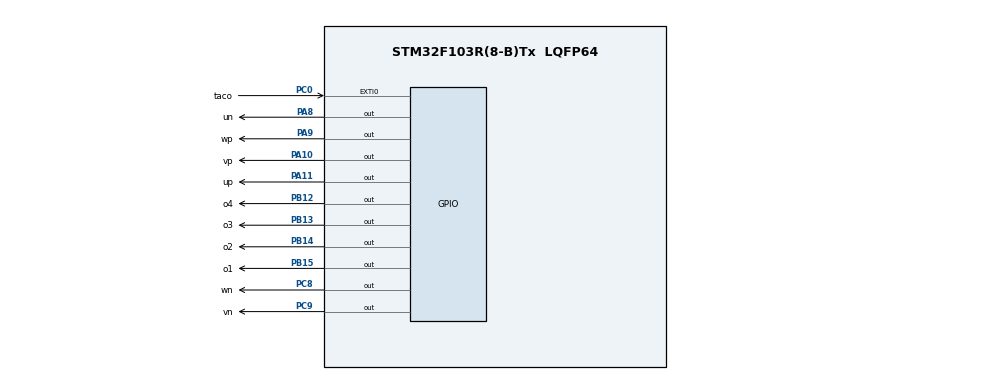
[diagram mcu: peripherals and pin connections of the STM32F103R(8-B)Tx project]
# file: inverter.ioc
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Mcu.Family=STM32F1
Mcu.Name=STM32F103R(8-B)Tx
Mcu.Package=LQFP64
NVIC.EXTI0_IRQn=true\:1\:0\:true\:false\:true\:true\:true
NVIC.PriorityGroup=NVIC_PRIORITYGROUP_4
NVIC.TIM1_UP_IRQn=true\:0\:0\:false\:false\:true\:true\:true
NVIC.TIM4_IRQn=true\:0\:0\:false\:false\:true\:false\:true
NVIC.TimeBase=TIM4_IRQn
NVIC.TimeBaseIP=TIM4
PA10.GPIO_Label=vp
PA10.GPIO_Speed=GPIO_SPEED_FREQ_HIGH
PA10.Signal=GPIO_Output
PA11.GPIO_Label=up
PA11.GPIO_Speed=GPIO_SPEED_FREQ_HIGH
PA11.Signal=GPIO_Output
PA13.Mode=Serial_Wire
PA13.Signal=SYS_JTMS-SWDIO
PA14.Mode=Serial_Wire
PA14.Signal=SYS_JTCK-SWCLK
PA8.GPIO_Label=un
PA8.GPIO_Speed=GPIO_SPEED_FREQ_HIGH
PA8.PinState=GPIO_PIN_RESET
PA8.Signal=GPIO_Output
PA9.GPIO_Label=wp
PA9.GPIO_Speed=GPIO_SPEED_FREQ_HIGH
PA9.Signal=GPIO_Output
PB12.GPIO_Label=o4
PB12.GPIO_Speed=GPIO_SPEED_FREQ_HIGH
PB12.Signal=GPIO_Output
PB13.GPIO_Label=o3
PB13.GPIO_Speed=GPIO_SPEED_FREQ_HIGH
PB13.Signal=GPIO_Output
PB14.GPIO_Label=o2
PB14.GPIO_Speed=GPIO_SPEED_FREQ_HIGH
PB14.Signal=GPIO_Output
PB15.GPIO_Label=o1
PB15.GPIO_Speed=GPIO_SPEED_FREQ_HIGH
PB15.Signal=GPIO_Output
PC0.GPIO_Label=taco
PC0.Signal=GPXTI0
PC8.GPIO_Label=wn
PC8.GPIO_Speed=GPIO_SPEED_FREQ_HIGH
PC8.Signal=GPIO_Output
PC9.GPIO_Label=vn
PC9.GPIO_Speed=GPIO_SPEED_FREQ_HIGH
PC9.Signal=GPIO_Output
PD0-OSC_IN.Mode=HSE-External-Oscillator
PD0-OSC_IN.Signal=RCC_OSC_IN
PD1-OSC_OUT.Mode=HSE-External-Oscillator
PD1-OSC_OUT.Signal=RCC_OSC_OUT
ProjectManager.HeapSize=0x200
ProjectManager.StackSize=0x400
ProjectManager.TargetToolchain=STM32CubeIDE
RCC.AHBFreq_Value=72000000
RCC.APB1CLKDivider=RCC_HCLK_DIV2
RCC.APB1Freq_Value=36000000
RCC.APB1TimFreq_Value=72000000
RCC.APB2Freq_Value=72000000
RCC.APB2TimFreq_Value=72000000
RCC.HCLKFreq_Value=72000000
RCC.PLLMUL=RCC_PLL_MUL9
RCC.PLLSourceVirtual=RCC_PLLSOURCE_HSE
RCC.SYSCLKFreq_VALUE=72000000
RCC.SYSCLKSource=RCC_SYSCLKSOURCE_PLLCLK
RCC.USBFreq_Value=72000000
TIM1.Period=0
TIM1.Prescaler=36
TIM1.RepetitionCounter=2
VP_SYS_VS_tim4.Mode=TIM4
VP_TIM1_VS_ClockSourceINT.Mode=Internal
board=custom

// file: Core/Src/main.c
/* USER CODE BEGIN Header */
/**
 ******************************************************************************
 * @file           : main.c
 * @brief          : Main program body
 ******************************************************************************
 * @attention
 *
 * <h2><center>&copy; Copyright (c) 2021 STMicroelectronics.
 * All rights reserved.</center></h2>
 *
 * This software component is licensed by ST under BSD 3-Clause license,
 * the "License"; You may not use this file except in compliance with the
 * License. You may obtain a copy of the License at:
 *                        opensource.org/licenses/BSD-3-Clause
 *
 ******************************************************************************
 */
/* USER CODE END Header */
#include "main.h"
#include "tim.h"
#include "gpio.h"

void SystemClock_Config(void);

int main(void)
{

	/* MCU Configuration--------------------------------------------------------*/

	/* Reset of all peripherals, Initializes the Flash interface and the Systick. */
	HAL_Init();

	/* Configure the system clock */
	SystemClock_Config();

	/* Initialize all configured peripherals */
	MX_GPIO_Init();
	MX_TIM1_Init();
	/* USER CODE BEGIN 2 */
	LL_TIM_EnableCounter(TIM1);
	LL_TIM_EnableIT_UPDATE(TIM1);
	/* USER CODE END 2 */

	/* Infinite loop */
	/* USER CODE BEGIN WHILE */

	//LL_GPIO_TogglePin(GPIOC, LL_GPIO_PIN_13);
	//LL_GPIO_SetOutputPin(o1_GPIO_Port, o1_Pin);
	//LL_GPIO_ResetOutputPin(o1_GPIO_Port, o1_Pin);
	while (1)
	{
		/* USER CODE END WHILE */

	}
}

void SystemClock_Config(void)
{
	LL_FLASH_SetLatency(LL_FLASH_LATENCY_2);
	while(LL_FLASH_GetLatency()!= LL_FLASH_LATENCY_2)
	{
	}
	LL_RCC_HSE_Enable();

	/* Wait till HSE is ready */
	while(LL_RCC_HSE_IsReady() != 1)
	{

	}
	LL_RCC_PLL_ConfigDomain_SYS(LL_RCC_PLLSOURCE_HSE_DIV_1, LL_RCC_PLL_MUL_9);
	LL_RCC_PLL_Enable();

	/* Wait till PLL is ready */
	while(LL_RCC_PLL_IsReady() != 1)
	{

	}
	LL_RCC_SetAHBPrescaler(LL_RCC_SYSCLK_DIV_1);
	LL_RCC_SetAPB1Prescaler(LL_RCC_APB1_DIV_2);
	LL_RCC_SetAPB2Prescaler(LL_RCC_APB2_DIV_1);
	LL_RCC_SetSysClkSource(LL_RCC_SYS_CLKSOURCE_PLL);

	/* Wait till System clock is ready */
	while(LL_RCC_GetSysClkSource() != LL_RCC_SYS_CLKSOURCE_STATUS_PLL)
	{

	}
	LL_SetSystemCoreClock(72000000);

	/* Update the time base */
	if (HAL_InitTick (TICK_INT_PRIORITY) != HAL_OK)
	{
		Error_Handler();
	}
}

void HAL_TIM_PeriodElapsedCallback(TIM_HandleTypeDef *htim)
{
	if (htim->Instance == TIM4) {
		HAL_IncTick();
	}
}

void Error_Handler(void)
{
	__disable_irq();
	while (1)
	{
	}
}

/************************ (C) COPYRIGHT STMicroelectronics *****END OF FILE****/
